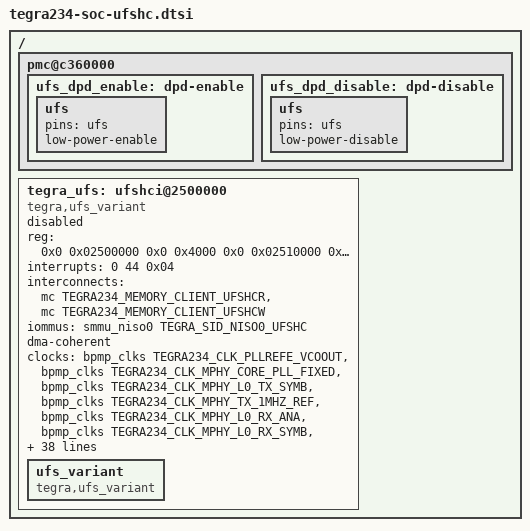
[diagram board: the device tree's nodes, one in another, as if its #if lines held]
/*
 * Copyright (c) 2017-2021, NVIDIA CORPORATION.  All rights reserved.
 *
 * This program is free software; you can redistribute it and/or modify it
 * under the terms and conditions of the GNU General Public License,
 * version 2, as published by the Free Software Foundation.
 *
 * This program is distributed in the hope it will be useful, but WITHOUT
 * ANY WARRANTY; without even the implied warranty of MERCHANTABILITY or
 * FITNESS FOR A PARTICULAR PURPOSE.  See the GNU General Public License for
 * more details.
 *
 * You should have received a copy of the GNU General Public License
 * along with this program.  If not, see <http://www.gnu.org/licenses/>.
 */

/*
 * tegra234-soc-ufshc.dtsi: Tegra234 soc dtsi file for UFS host controller
 */

/ {

	pmc@c360000 {
		ufs_dpd_enable: dpd-enable {
			ufs {
				pins = "ufs";
				low-power-enable;
			};
		};
		ufs_dpd_disable: dpd-disable {
			ufs {
				pins = "ufs";
				low-power-disable;
			};
		};
	};

	tegra_ufs: ufshci@2500000 {
		compatible = "tegra,ufs_variant";
		reg = <0x0 0x02500000 0x0 0x4000        /* UFSHC_MMIO Registers (16K) */
			0x0 0x02510000 0x0 0x1000       /* UFSHC_AUX Registers (4K) */
			 0x0 0x02518000 0x0 0x1000      /* UFSHC_FPGA Registers (4K) */
			  0x0 0x02520000 0x0 0x1000     /* UFSHC_VIRT Registers (4K) */
			   0x0 0x02470000 0x0 0x4000    /* MPHY_L0 Registers (16K) */
			    0x0 0x02480000 0x0 0x4000>; /* MPHY_L1 Registers (16K) */
		interrupts = < 0 44 0x04 >;
#if TEGRA_IOMMU_DT_VERSION >= DT_VERSION_2
		interconnects = <&mc TEGRA234_MEMORY_CLIENT_UFSHCR>,
			        <&mc TEGRA234_MEMORY_CLIENT_UFSHCW>;
		interconnect-names = "dma-mem", "dma-mem";
#endif

		iommus = <&smmu_niso0 TEGRA_SID_NISO0_UFSHC>;
		dma-coherent;
		clocks = <&bpmp_clks TEGRA234_CLK_PLLREFE_VCOOUT>,
				<&bpmp_clks TEGRA234_CLK_MPHY_CORE_PLL_FIXED>,
				<&bpmp_clks TEGRA234_CLK_MPHY_L0_TX_SYMB>,
				<&bpmp_clks TEGRA234_CLK_MPHY_TX_1MHZ_REF> ,
				<&bpmp_clks TEGRA234_CLK_MPHY_L0_RX_ANA>,
				<&bpmp_clks TEGRA234_CLK_MPHY_L0_RX_SYMB>,
				<&bpmp_clks TEGRA234_CLK_MPHY_L0_TX_LS_3XBIT>,
				<&bpmp_clks TEGRA234_CLK_MPHY_L0_RX_LS_BIT>,
				<&bpmp_clks TEGRA234_CLK_MPHY_L1_RX_ANA>,
				<&bpmp_clks TEGRA234_CLK_UFSHC>,
				<&bpmp_clks TEGRA234_CLK_UFSDEV_REF>,
				<&bpmp_clks TEGRA234_CLK_PLLP_OUT0>,
				<&bpmp_clks TEGRA234_CLK_CLK_M>,
				<&bpmp_clks TEGRA234_CLK_MPHY_FORCE_LS_MODE>,
				<&bpmp_clks TEGRA234_CLK_UPHY_PLL3>,
				<&bpmp_clks TEGRA234_CLK_MPHY_L0_TX_LS_3XBIT_DIV>,
				<&bpmp_clks TEGRA234_CLK_MPHY_L0_TX_LS_SYMB_DIV>,
				<&bpmp_clks TEGRA234_CLK_MPHY_L0_RX_LS_BIT_DIV>,
				<&bpmp_clks TEGRA234_CLK_MPHY_L0_RX_LS_SYMB_DIV>,
				<&bpmp_clks TEGRA234_CLK_MPHY_L0_TX_2X_SYMB>,
				<&bpmp_clks TEGRA234_CLK_MPHY_L0_TX_HS_SYMB_DIV>,
				<&bpmp_clks TEGRA234_CLK_MPHY_L0_RX_HS_SYMB_DIV>,
				<&bpmp_clks TEGRA234_CLK_MPHY_L0_TX_MUX_SYMB_DIV>,
				<&bpmp_clks TEGRA234_CLK_MPHY_L0_RX_MUX_SYMB_DIV>,
				<&bpmp_clks TEGRA234_CLK_OSC>;
		clock-names = "pllrefe_vcoout", "mphy_core_pll_fixed", "mphy_l0_tx_symb",
				"mphy_tx_1mhz_ref", "mphy_l0_rx_ana",
				"mphy_l0_rx_symb", "mphy_l0_tx_ls_3xbit",
				"mphy_l0_rx_ls_bit", "mphy_l1_rx_ana",
				"ufshc", "ufsdev_ref", "pll_p", "clk_m",
				"mphy_force_ls_mode", "uphy_pll3",
				"mphy_l0_tx_ls_3xbit_div", "mphy_l0_tx_ls_symb_div",
				"mphy_l0_rx_ls_bit_div", "mphy_l0_rx_ls_symb_div", "mphy_l0_tx_2x_symb",
				"mphy_l0_tx_hs_symb_div", "mphy_l0_rx_hs_symb_div",
				"mphy_l0_tx_mux_symb_div", "mphy_l0_rx_mux_symb_div", "osc";
		resets = <&bpmp_resets TEGRA234_RESET_MPHY_L0_RX>,
				<&bpmp_resets TEGRA234_RESET_MPHY_L0_TX>,
				<&bpmp_resets TEGRA234_RESET_MPHY_L1_RX>,
				<&bpmp_resets TEGRA234_RESET_MPHY_L1_TX>,
				<&bpmp_resets TEGRA234_RESET_MPHY_CLK_CTL>,
				<&bpmp_resets TEGRA234_RESET_UFSHC>,
				<&bpmp_resets TEGRA234_RESET_UFSHC_AXI_M>,
				<&bpmp_resets TEGRA234_RESET_UFSHC_LP_SEQ>;
		reset-names = "mphy-l0-rx-rst", "mphy-l0-tx-rst", "mphy-l1-rx-rst",
				"mphy-l1-tx-rst", "mphy-clk-ctl-rst", "ufs-rst",
				"ufs-axi-m-rst", "ufshc-lp-rst";
		nvidia,enable-x2-config;
		nvidia,mask-fast-auto-mode;
		nvidia,enable-hs-mode;
		nvidia,enable-38mhz-clk;
		nvidia,enable-rx-calib;
		nvidia,max-hs-gear = <4>;
		nvidia,max-pwm-gear = <0>;
		vcc-max-microamp = <0>;
		vccq-max-microamp = <0>;
		vccq2-max-microamp = <0>;
		nvidia,configure-uphy-pll3;
		status = "disabled";

		ufs_variant {
			compatible = "tegra,ufs_variant";
		};
	};
};

